AUTOSAR XML (schema 3.1.2)
package /Components/SWC_VSCo
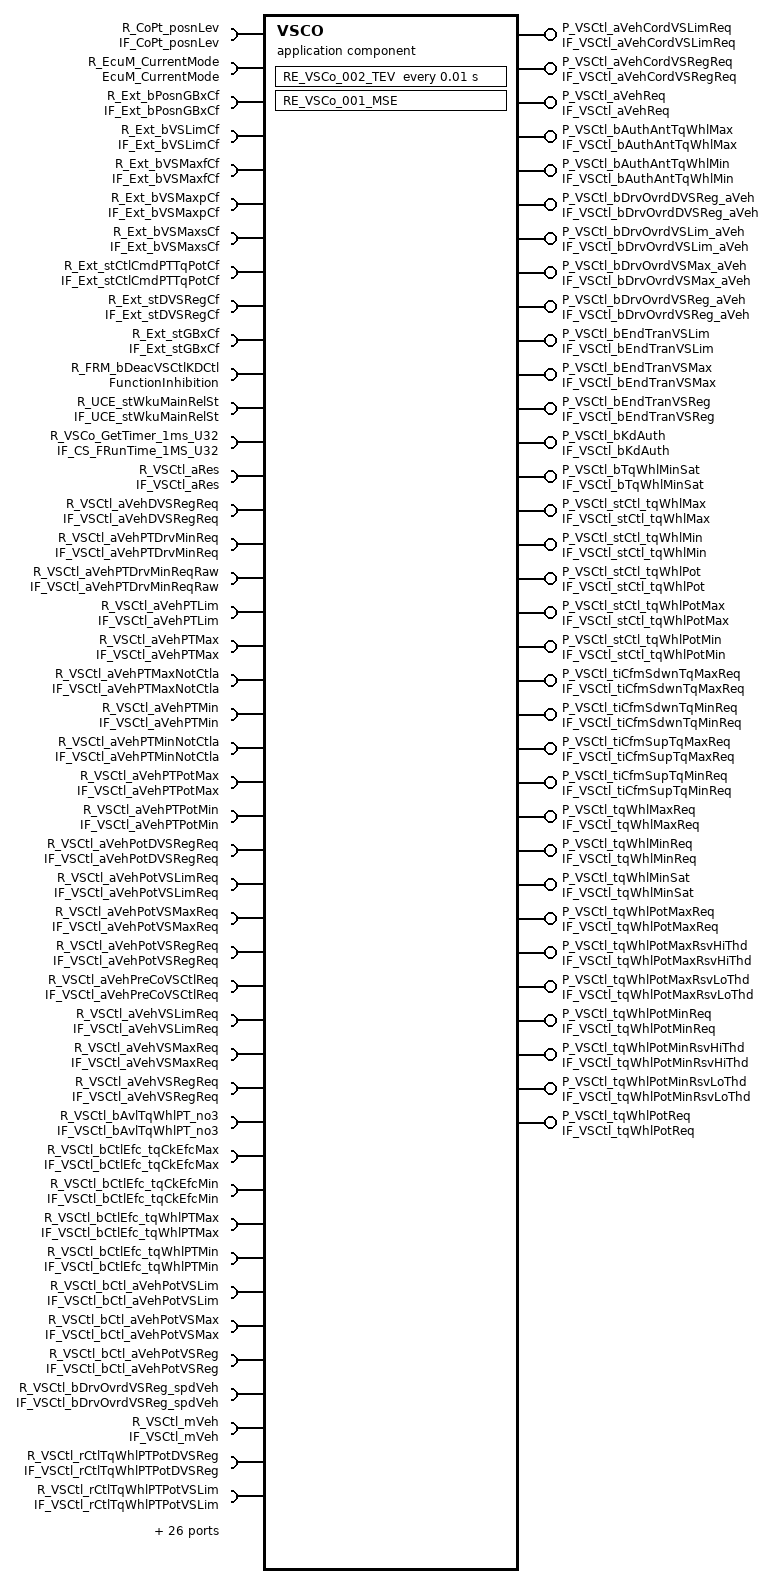
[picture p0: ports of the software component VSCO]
  application software component type VSCO  # VSCo
    33 x provide port:
      P_VSCtl_aVehCordVSLimReq: unqueued-sender-com-spec{data-element=VSCtl_aVehCordVSLimReq, can-invalidate=false, init-value=C_SInt16_10240}, provided-interface=IF_VSCtl_aVehCordVSLimReq
      P_VSCtl_aVehCordVSRegReq: unqueued-sender-com-spec{data-element=VSCtl_aVehCordVSRegReq, can-invalidate=false, init-value=C_SInt16_m10240}, provided-interface=IF_VSCtl_aVehCordVSRegReq
      P_VSCtl_aVehReq: unqueued-sender-com-spec{data-element=VSCtl_aVehReq, can-invalidate=false, init-value=C_SInt16_m102401}, provided-interface=IF_VSCtl_aVehReq
      P_VSCtl_bAuthAntTqWhlMax: unqueued-sender-com-spec{data-element=VSCtl_bAuthAntTqWhlMax, can-invalidate=false, init-value=C_Boolean_False}, provided-interface=IF_VSCtl_bAuthAntTqWhlMax
      P_VSCtl_bAuthAntTqWhlMin: unqueued-sender-com-spec{data-element=VSCtl_bAuthAntTqWhlMin, can-invalidate=false, init-value=C_Boolean_False3}, provided-interface=IF_VSCtl_bAuthAntTqWhlMin
      P_VSCtl_bDrvOvrdDVSReg_aVeh: unqueued-sender-com-spec{data-element=VSCtl_bDrvOvrdDVSReg_aVeh, can-invalidate=false, init-value=C_Boolean_False5}, provided-interface=IF_VSCtl_bDrvOvrdDVSReg_aVeh
      P_VSCtl_bDrvOvrdVSLim_aVeh: unqueued-sender-com-spec{data-element=VSCtl_bDrvOvrdVSLim_aVeh, can-invalidate=false, init-value=C_Boolean_True}, provided-interface=IF_VSCtl_bDrvOvrdVSLim_aVeh
      P_VSCtl_bDrvOvrdVSMax_aVeh: unqueued-sender-com-spec{data-element=VSCtl_bDrvOvrdVSMax_aVeh, can-invalidate=false, init-value=C_Boolean_True7}, provided-interface=IF_VSCtl_bDrvOvrdVSMax_aVeh
      P_VSCtl_bDrvOvrdVSReg_aVeh: unqueued-sender-com-spec{data-element=VSCtl_bDrvOvrdVSReg_aVeh, can-invalidate=false, init-value=C_Boolean_False9}, provided-interface=IF_VSCtl_bDrvOvrdVSReg_aVeh
      P_VSCtl_bEndTranVSLim: unqueued-sender-com-spec{data-element=VSCtl_bEndTranVSLim, can-invalidate=false, init-value=C_Boolean_True11}, provided-interface=IF_VSCtl_bEndTranVSLim
      P_VSCtl_bEndTranVSMax: unqueued-sender-com-spec{data-element=VSCtl_bEndTranVSMax, can-invalidate=false, init-value=C_Boolean_True13}, provided-interface=IF_VSCtl_bEndTranVSMax
      P_VSCtl_bEndTranVSReg: unqueued-sender-com-spec{data-element=VSCtl_bEndTranVSReg, can-invalidate=false, init-value=C_Boolean_True15}, provided-interface=IF_VSCtl_bEndTranVSReg
      P_VSCtl_bKdAuth: unqueued-sender-com-spec{data-element=VSCtl_bKdAuth, can-invalidate=false, init-value=C_Boolean_False17}, provided-interface=IF_VSCtl_bKdAuth
      P_VSCtl_bTqWhlMinSat: unqueued-sender-com-spec{data-element=VSCtl_bTqWhlMinSat, can-invalidate=false, init-value=C_Boolean_False19}, provided-interface=IF_VSCtl_bTqWhlMinSat
      P_VSCtl_stCtl_tqWhlMax: unqueued-sender-com-spec{data-element=VSCtl_stCtl_tqWhlMax, can-invalidate=false, init-value=C_Boolean_False21}, provided-interface=IF_VSCtl_stCtl_tqWhlMax
      P_VSCtl_stCtl_tqWhlMin: unqueued-sender-com-spec{data-element=VSCtl_stCtl_tqWhlMin, can-invalidate=false, init-value=C_Boolean_False23}, provided-interface=IF_VSCtl_stCtl_tqWhlMin
      P_VSCtl_stCtl_tqWhlPot: unqueued-sender-com-spec{data-element=VSCtl_stCtl_tqWhlPot, can-invalidate=false, init-value=C_Boolean_False25}, provided-interface=IF_VSCtl_stCtl_tqWhlPot
      P_VSCtl_stCtl_tqWhlPotMax: unqueued-sender-com-spec{data-element=VSCtl_stCtl_tqWhlPotMax, can-invalidate=false, init-value=C_UInt8_0}, provided-interface=IF_VSCtl_stCtl_tqWhlPotMax
      P_VSCtl_stCtl_tqWhlPotMin: unqueued-sender-com-spec{data-element=VSCtl_stCtl_tqWhlPotMin, can-invalidate=false, init-value=C_UInt8_027}, provided-interface=IF_VSCtl_stCtl_tqWhlPotMin
      P_VSCtl_tiCfmSdwnTqMaxReq: unqueued-sender-com-spec{data-element=VSCtl_tiCfmSdwnTqMaxReq, can-invalidate=false, init-value=C_UInt16_0}, provided-interface=IF_VSCtl_tiCfmSdwnTqMaxReq
      P_VSCtl_tiCfmSdwnTqMinReq: unqueued-sender-com-spec{data-element=VSCtl_tiCfmSdwnTqMinReq, can-invalidate=false, init-value=C_UInt16_029}, provided-interface=IF_VSCtl_tiCfmSdwnTqMinReq
      P_VSCtl_tiCfmSupTqMaxReq: unqueued-sender-com-spec{data-element=VSCtl_tiCfmSupTqMaxReq, can-invalidate=false, init-value=C_UInt16_031}, provided-interface=IF_VSCtl_tiCfmSupTqMaxReq
      P_VSCtl_tiCfmSupTqMinReq: unqueued-sender-com-spec{data-element=VSCtl_tiCfmSupTqMinReq, can-invalidate=false, init-value=C_UInt16_033}, provided-interface=IF_VSCtl_tiCfmSupTqMinReq
      P_VSCtl_tqWhlMaxReq: unqueued-sender-com-spec{data-element=VSCtl_tqWhlMaxReq, can-invalidate=false, init-value=C_SInt16_32000}, provided-interface=IF_VSCtl_tqWhlMaxReq
      P_VSCtl_tqWhlMinReq: unqueued-sender-com-spec{data-element=VSCtl_tqWhlMinReq, can-invalidate=false, init-value=C_SInt16_m32000}, provided-interface=IF_VSCtl_tqWhlMinReq
      P_VSCtl_tqWhlMinSat: unqueued-sender-com-spec{data-element=VSCtl_tqWhlMinSat, can-invalidate=false, init-value=C_SInt16_m3200035}, provided-interface=IF_VSCtl_tqWhlMinSat
      P_VSCtl_tqWhlPotMaxReq: unqueued-sender-com-spec{data-element=VSCtl_tqWhlPotMaxReq, can-invalidate=false, init-value=C_SInt16_3200037}, provided-interface=IF_VSCtl_tqWhlPotMaxReq
      P_VSCtl_tqWhlPotMaxRsvHiThd: unqueued-sender-com-spec{data-element=VSCtl_tqWhlPotMaxRsvHiThd, can-invalidate=false, init-value=C_SInt16_0}, provided-interface=IF_VSCtl_tqWhlPotMaxRsvHiThd
      P_VSCtl_tqWhlPotMaxRsvLoThd: unqueued-sender-com-spec{data-element=VSCtl_tqWhlPotMaxRsvLoThd, can-invalidate=false, init-value=C_SInt16_039}, provided-interface=IF_VSCtl_tqWhlPotMaxRsvLoThd
      P_VSCtl_tqWhlPotMinReq: unqueued-sender-com-spec{data-element=VSCtl_tqWhlPotMinReq, can-invalidate=false, init-value=C_SInt16_m3200041}, provided-interface=IF_VSCtl_tqWhlPotMinReq
      P_VSCtl_tqWhlPotMinRsvHiThd: unqueued-sender-com-spec{data-element=VSCtl_tqWhlPotMinRsvHiThd, can-invalidate=false, init-value=C_SInt16_043}, provided-interface=IF_VSCtl_tqWhlPotMinRsvHiThd
      P_VSCtl_tqWhlPotMinRsvLoThd: unqueued-sender-com-spec{data-element=VSCtl_tqWhlPotMinRsvLoThd, can-invalidate=false, init-value=C_SInt16_045}, provided-interface=IF_VSCtl_tqWhlPotMinRsvLoThd
      P_VSCtl_tqWhlPotReq: unqueued-sender-com-spec{data-element=VSCtl_tqWhlPotReq, can-invalidate=false, init-value=C_SInt16_m3200047}, provided-interface=IF_VSCtl_tqWhlPotReq
    70 x require port:
      R_CoPt_posnLev: unqueued-receiver-com-spec{data-element=CoPt_posnLev, init-value=ConstantValue, resync-time=0}, required-interface=IF_CoPt_posnLev
      R_EcuM_CurrentMode: required-interface=EcuM_CurrentMode  # Requirement: 01552_09_00532-SSTG-C007(2)
      R_Ext_bPosnGBxCf: unqueued-receiver-com-spec{data-element=Ext_bPosnGBxCf, init-value=C_Boolean_False49, resync-time=0}, required-interface=IF_Ext_bPosnGBxCf
      R_Ext_bVSLimCf: unqueued-receiver-com-spec{data-element=Ext_bVSLimCf, init-value=C_Boolean_False51, resync-time=0}, required-interface=IF_Ext_bVSLimCf
      R_Ext_bVSMaxfCf: unqueued-receiver-com-spec{data-element=Ext_bVSMaxfCf, init-value=C_Boolean_False53, resync-time=0}, required-interface=IF_Ext_bVSMaxfCf
      R_Ext_bVSMaxpCf: unqueued-receiver-com-spec{data-element=Ext_bVSMaxpCf, init-value=C_Boolean_False55, resync-time=0}, required-interface=IF_Ext_bVSMaxpCf
      R_Ext_bVSMaxsCf: unqueued-receiver-com-spec{data-element=Ext_bVSMaxsCf, init-value=C_Boolean_False57, resync-time=0}, required-interface=IF_Ext_bVSMaxsCf
      R_Ext_stCtlCmdPTTqPotCf: unqueued-receiver-com-spec{data-element=Ext_stCtlCmdPTTqPotCf, init-value=C_UInt8_059, resync-time=0}, required-interface=IF_Ext_stCtlCmdPTTqPotCf
      R_Ext_stDVSRegCf: unqueued-receiver-com-spec{data-element=Ext_stDVSRegCf, init-value=C_UInt8_061, resync-time=0}, required-interface=IF_Ext_stDVSRegCf
      R_Ext_stGBxCf: unqueued-receiver-com-spec{data-element=Ext_stGBxCf, init-value=ConstantValue63, resync-time=0}, required-interface=IF_Ext_stGBxCf
      R_FRM_bDeacVSCtlKDCtl: required-interface=FunctionInhibition
      R_UCE_stWkuMainRelSt: required-interface=IF_UCE_stWkuMainRelSt  # Requirement: 01552_09_00532-SSTG-C011(1)
      R_VSCo_GetTimer_1ms_U32: required-interface=IF_CS_FRunTime_1MS_U32
      R_VSCtl_aRes: unqueued-receiver-com-spec{data-element=VSCtl_aRes, init-value=C_SInt16_m1024065, resync-time=0}, required-interface=IF_VSCtl_aRes
      R_VSCtl_aVehDVSRegReq: unqueued-receiver-com-spec{data-element=VSCtl_aVehDVSRegReq, init-value=C_SInt16_m1024067, resync-time=0}, required-interface=IF_VSCtl_aVehDVSRegReq
      R_VSCtl_aVehPTDrvMinReq: unqueued-receiver-com-spec{data-element=VSCtl_aVehPTDrvMinReq, init-value=C_SInt16_m1024069, resync-time=0}, required-interface=IF_VSCtl_aVehPTDrvMinReq
      R_VSCtl_aVehPTDrvMinReqRaw: unqueued-receiver-com-spec{data-element=VSCtl_aVehPTDrvMinReqRaw, init-value=C_SInt16_m1024071, resync-time=0}, required-interface=IF_VSCtl_aVehPTDrvMinReqRaw
      R_VSCtl_aVehPTLim: unqueued-receiver-com-spec{data-element=VSCtl_aVehPTLim, init-value=C_SInt16_m1024073, resync-time=0}, required-interface=IF_VSCtl_aVehPTLim
      R_VSCtl_aVehPTMax: unqueued-receiver-com-spec{data-element=VSCtl_aVehPTMax, init-value=C_SInt16_m1024075, resync-time=0}, required-interface=IF_VSCtl_aVehPTMax
      R_VSCtl_aVehPTMaxNotCtla: unqueued-receiver-com-spec{data-element=VSCtl_aVehPTMaxNotCtla, init-value=C_SInt16_m1024077, resync-time=0}, required-interface=IF_VSCtl_aVehPTMaxNotCtla
      R_VSCtl_aVehPTMin: unqueued-receiver-com-spec{data-element=VSCtl_aVehPTMin, init-value=C_SInt16_m1024079, resync-time=0}, required-interface=IF_VSCtl_aVehPTMin
      R_VSCtl_aVehPTMinNotCtla: unqueued-receiver-com-spec{data-element=VSCtl_aVehPTMinNotCtla, init-value=C_SInt16_m1024081, resync-time=0}, required-interface=IF_VSCtl_aVehPTMinNotCtla
      R_VSCtl_aVehPTPotMax: unqueued-receiver-com-spec{data-element=VSCtl_aVehPTPotMax, init-value=C_SInt16_m1024083, resync-time=0}, required-interface=IF_VSCtl_aVehPTPotMax
      R_VSCtl_aVehPTPotMin: unqueued-receiver-com-spec{data-element=VSCtl_aVehPTPotMin, init-value=C_SInt16_m1024085, resync-time=0}, required-interface=IF_VSCtl_aVehPTPotMin
      R_VSCtl_aVehPotDVSRegReq: unqueued-receiver-com-spec{data-element=VSCtl_aVehPotDVSRegReq, init-value=C_SInt16_m1024087, resync-time=0}, required-interface=IF_VSCtl_aVehPotDVSRegReq
      R_VSCtl_aVehPotVSLimReq: unqueued-receiver-com-spec{data-element=VSCtl_aVehPotVSLimReq, init-value=C_SInt16_m1024089, resync-time=0}, required-interface=IF_VSCtl_aVehPotVSLimReq
      R_VSCtl_aVehPotVSMaxReq: unqueued-receiver-com-spec{data-element=VSCtl_aVehPotVSMaxReq, init-value=C_SInt16_m1024091, resync-time=0}, required-interface=IF_VSCtl_aVehPotVSMaxReq
      R_VSCtl_aVehPotVSRegReq: unqueued-receiver-com-spec{data-element=VSCtl_aVehPotVSRegReq, init-value=C_SInt16_m1024093, resync-time=0}, required-interface=IF_VSCtl_aVehPotVSRegReq
      R_VSCtl_aVehPreCoVSCtlReq: unqueued-receiver-com-spec{data-element=VSCtl_aVehPreCoVSCtlReq, init-value=C_SInt16_m1024095, resync-time=0}, required-interface=IF_VSCtl_aVehPreCoVSCtlReq
      R_VSCtl_aVehVSLimReq: unqueued-receiver-com-spec{data-element=VSCtl_aVehVSLimReq, init-value=C_SInt16_m1024097, resync-time=0}, required-interface=IF_VSCtl_aVehVSLimReq
      R_VSCtl_aVehVSMaxReq: unqueued-receiver-com-spec{data-element=VSCtl_aVehVSMaxReq, init-value=C_SInt16_m1024099, resync-time=0}, required-interface=IF_VSCtl_aVehVSMaxReq
      R_VSCtl_aVehVSRegReq: unqueued-receiver-com-spec{data-element=VSCtl_aVehVSRegReq, init-value=C_SInt16_m10240101, resync-time=0}, required-interface=IF_VSCtl_aVehVSRegReq
      R_VSCtl_bAvlTqWhlPT_no3: unqueued-receiver-com-spec{data-element=VSCtl_bAvlTqWhlPT_no3, init-value=C_Boolean_False103, resync-time=0}, required-interface=IF_VSCtl_bAvlTqWhlPT_no3
      R_VSCtl_bCtlEfc_tqCkEfcMax: unqueued-receiver-com-spec{data-element=VSCtl_bCtlEfc_tqCkEfcMax, init-value=C_Boolean_False105, resync-time=0}, required-interface=IF_VSCtl_bCtlEfc_tqCkEfcMax
      R_VSCtl_bCtlEfc_tqCkEfcMin: unqueued-receiver-com-spec{data-element=VSCtl_bCtlEfc_tqCkEfcMin, init-value=C_Boolean_False107, resync-time=0}, required-interface=IF_VSCtl_bCtlEfc_tqCkEfcMin
      R_VSCtl_bCtlEfc_tqWhlPTMax: unqueued-receiver-com-spec{data-element=VSCtl_bCtlEfc_tqWhlPTMax, init-value=C_Boolean_False109, resync-time=0}, required-interface=IF_VSCtl_bCtlEfc_tqWhlPTMax
      R_VSCtl_bCtlEfc_tqWhlPTMin: unqueued-receiver-com-spec{data-element=VSCtl_bCtlEfc_tqWhlPTMin, init-value=C_Boolean_False111, resync-time=0}, required-interface=IF_VSCtl_bCtlEfc_tqWhlPTMin
      R_VSCtl_bCtl_aVehPotVSLim: unqueued-receiver-com-spec{data-element=VSCtl_bCtl_aVehPotVSLim, init-value=C_UInt8_0113, resync-time=0}, required-interface=IF_VSCtl_bCtl_aVehPotVSLim
      R_VSCtl_bCtl_aVehPotVSMax: unqueued-receiver-com-spec{data-element=VSCtl_bCtl_aVehPotVSMax, init-value=C_UInt8_0115, resync-time=0}, required-interface=IF_VSCtl_bCtl_aVehPotVSMax
      R_VSCtl_bCtl_aVehPotVSReg: unqueued-receiver-com-spec{data-element=VSCtl_bCtl_aVehPotVSReg, init-value=C_UInt8_0117, resync-time=0}, required-interface=IF_VSCtl_bCtl_aVehPotVSReg
      R_VSCtl_bDrvOvrdVSReg_spdVeh: unqueued-receiver-com-spec{data-element=VSCtl_bDrvOvrdVSReg_spdVeh, init-value=C_Boolean_False119, resync-time=0}, required-interface=IF_VSCtl_bDrvOvrdVSReg_spdVeh
      R_VSCtl_mVeh: unqueued-receiver-com-spec{data-element=VSCtl_mVeh, init-value=C_UInt16_1, resync-time=0}, required-interface=IF_VSCtl_mVeh
      R_VSCtl_rCtlTqWhlPTPotDVSReg: unqueued-receiver-com-spec{data-element=VSCtl_rCtlTqWhlPTPotDVSReg, init-value=C_UInt16_0121, resync-time=0}, required-interface=IF_VSCtl_rCtlTqWhlPTPotDVSReg
      R_VSCtl_rCtlTqWhlPTPotVSLim: unqueued-receiver-com-spec{data-element=VSCtl_rCtlTqWhlPTPotVSLim, init-value=C_UInt16_0123, resync-time=0}, required-interface=IF_VSCtl_rCtlTqWhlPTPotVSLim
      R_VSCtl_rCtlTqWhlPTPotVSMax: unqueued-receiver-com-spec{data-element=VSCtl_rCtlTqWhlPTPotVSMax, init-value=C_UInt16_0125, resync-time=0}, required-interface=IF_VSCtl_rCtlTqWhlPTPotVSMax
      R_VSCtl_rCtlTqWhlPTPotVSReg: unqueued-receiver-com-spec{data-element=VSCtl_rCtlTqWhlPTPotVSReg, init-value=C_UInt16_0127, resync-time=0}, required-interface=IF_VSCtl_rCtlTqWhlPTPotVSReg
      R_VSCtl_rdWhl: unqueued-receiver-com-spec{data-element=VSCtl_rdWhl, init-value=C_UInt16_1129, resync-time=0}, required-interface=IF_VSCtl_rdWhl
      R_VSCtl_spdVeh: unqueued-receiver-com-spec{data-element=VSCtl_spdVeh, init-value=C_UInt16_0131, resync-time=0}, required-interface=IF_VSCtl_spdVeh
      R_VSCtl_stCtl_aVehDVSReg: unqueued-receiver-com-spec{data-element=VSCtl_stCtl_aVehDVSReg, init-value=C_Boolean_False133, resync-time=0}, required-interface=IF_VSCtl_stCtl_aVehDVSReg
      R_VSCtl_stCtl_aVehPotDVSReg: unqueued-receiver-com-spec{data-element=VSCtl_stCtl_aVehPotDVSReg, init-value=C_UInt8_0135, resync-time=0}, required-interface=IF_VSCtl_stCtl_aVehPotDVSReg
      R_VSCtl_stCtl_aVehVSLim: unqueued-receiver-com-spec{data-element=VSCtl_stCtl_aVehVSLim, init-value=C_UInt8_0137, resync-time=0}, required-interface=IF_VSCtl_stCtl_aVehVSLim
      R_VSCtl_stCtl_aVehVSMax: unqueued-receiver-com-spec{data-element=VSCtl_stCtl_aVehVSMax, init-value=C_UInt8_0139, resync-time=0}, required-interface=IF_VSCtl_stCtl_aVehVSMax
      R_VSCtl_stCtl_aVehVSReg: unqueued-receiver-com-spec{data-element=VSCtl_stCtl_aVehVSReg, init-value=C_UInt8_0141, resync-time=0}, required-interface=IF_VSCtl_stCtl_aVehVSReg
      R_VSCtl_stTqWhlPTCutOffReq: unqueued-receiver-com-spec{data-element=VSCtl_stTqWhlPTCutOffReq, init-value=C_UInt8_0143, resync-time=0}, required-interface=IF_VSCtl_stTqWhlPTCutOffReq
      R_VSCtl_stVSCtlInfo: unqueued-receiver-com-spec{data-element=VSCtl_stVSCtlInfo, init-value=C_UInt8_0145, resync-time=0}, required-interface=IF_VSCtl_stVSCtlInfo
      R_VSCtl_tiCfmSdwnDVSRegReq: unqueued-receiver-com-spec{data-element=VSCtl_tiCfmSdwnDVSRegReq, init-value=C_UInt16_0147, resync-time=0}, required-interface=IF_VSCtl_tiCfmSdwnDVSRegReq
      R_VSCtl_tiCfmSdwnVSLimReq: unqueued-receiver-com-spec{data-element=VSCtl_tiCfmSdwnVSLimReq, init-value=C_UInt16_0149, resync-time=0}, required-interface=IF_VSCtl_tiCfmSdwnVSLimReq
      R_VSCtl_tiCfmSdwnVSMaxReq: unqueued-receiver-com-spec{data-element=VSCtl_tiCfmSdwnVSMaxReq, init-value=C_UInt16_0151, resync-time=0}, required-interface=IF_VSCtl_tiCfmSdwnVSMaxReq
      R_VSCtl_tiCfmSdwnVSRegReq: unqueued-receiver-com-spec{data-element=VSCtl_tiCfmSdwnVSRegReq, init-value=C_UInt16_0153, resync-time=0}, required-interface=IF_VSCtl_tiCfmSdwnVSRegReq
      R_VSCtl_tiCfmSupDVSRegReq: unqueued-receiver-com-spec{data-element=VSCtl_tiCfmSupDVSRegReq, init-value=C_UInt16_0155, resync-time=0}, required-interface=IF_VSCtl_tiCfmSupDVSRegReq
      R_VSCtl_tiCfmSupVSLimReq: unqueued-receiver-com-spec{data-element=VSCtl_tiCfmSupVSLimReq, init-value=C_UInt16_0157, resync-time=0}, required-interface=IF_VSCtl_tiCfmSupVSLimReq
      R_VSCtl_tiCfmSupVSMaxReq: unqueued-receiver-com-spec{data-element=VSCtl_tiCfmSupVSMaxReq, init-value=C_UInt16_0159, resync-time=0}, required-interface=IF_VSCtl_tiCfmSupVSMaxReq
      R_VSCtl_tiCfmSupVSRegReq: unqueued-receiver-com-spec{data-element=VSCtl_tiCfmSupVSRegReq, init-value=C_UInt16_0161, resync-time=0}, required-interface=IF_VSCtl_tiCfmSupVSRegReq
      R_VSCtl_tqWhlPTMax: unqueued-receiver-com-spec{data-element=VSCtl_tqWhlPTMax, init-value=C_SInt16_m32000163, resync-time=0}, required-interface=IF_VSCtl_tqWhlPTMax
      R_VSCtl_tqWhlPTMin: unqueued-receiver-com-spec{data-element=VSCtl_tqWhlPTMin, init-value=C_SInt16_m32000165, resync-time=0}, required-interface=IF_VSCtl_tqWhlPTMin
      R_VSCtl_tqWhlPTPotMax: unqueued-receiver-com-spec{data-element=VSCtl_tqWhlPTPotMax, init-value=C_SInt16_m32000167, resync-time=0}, required-interface=IF_VSCtl_tqWhlPTPotMax
      R_VSCtl_tqWhlPTPotMin: unqueued-receiver-com-spec{data-element=VSCtl_tqWhlPTPotMin, init-value=C_SInt16_m32000169, resync-time=0}, required-interface=IF_VSCtl_tqWhlPTPotMin
      R_VSCtl_tqWhlThPTMin: unqueued-receiver-com-spec{data-element=VSCtl_tqWhlThPTMin, init-value=C_SInt16_m32000171, resync-time=0}, required-interface=IF_VSCtl_tqWhlThPTMin
      R_VSCtl_tqWhlThPTPotMin: unqueued-receiver-com-spec{data-element=VSCtl_tqWhlThPTPotMin, init-value=C_SInt16_m32000173, resync-time=0}, required-interface=IF_VSCtl_tqWhlThPTPotMin
      R_Ext_bCtlCmdPTTqCf: unqueued-receiver-com-spec{data-element=Ext_bCtlCmdPTTqCf, init-value=ConstantValue175, resync-time=0}, required-interface=IF_Ext_bCtlCmdPTTqCf  # R_Ext_bVSMaxpCf
  99 x constant specification:
    C_Boolean_False
      value:
        boolean literal C_Boolean_False: type=DT_VSCtl_bAuthAntTqWhlMax, value=false
    C_Boolean_False103
      value:
        boolean literal C_Boolean_False103: type=DT_VSCtl_bAvlTqWhlPT_no3, value=false
    C_Boolean_False105
      value:
        boolean literal C_Boolean_False105: type=DT_VSCtl_bCtlEfc_tqCkEfcMax, value=false
    C_Boolean_False107
      value:
        boolean literal C_Boolean_False107: type=DT_VSCtl_bCtlEfc_tqCkEfcMin, value=false
    C_Boolean_False109
      value:
        boolean literal C_Boolean_False109: type=DT_VSCtl_bCtlEfc_tqWhlPTMax, value=false
    C_Boolean_False111
      value:
        boolean literal C_Boolean_False111: type=DT_VSCtl_bCtlEfc_tqWhlPTMin, value=false
    C_Boolean_False119
      value:
        boolean literal C_Boolean_False119: type=DT_VSCtl_bDrvOvrdVSReg_spdVeh, value=false
    C_Boolean_False133
      value:
        boolean literal C_Boolean_False133: type=DT_VSCtl_stCtl_aVehDVSReg, value=false
    C_Boolean_False17
      value:
        boolean literal C_Boolean_False17: type=DT_VSCtl_bKdAuth, value=false
    C_Boolean_False19
      value:
        boolean literal C_Boolean_False19: type=DT_VSCtl_bTqWhlMinSat, value=false
    C_Boolean_False21
      value:
        boolean literal C_Boolean_False21: type=DT_VSCtl_stCtl_tqWhlMax, value=false
    C_Boolean_False23
      value:
        boolean literal C_Boolean_False23: type=DT_VSCtl_stCtl_tqWhlMin, value=false
    C_Boolean_False25
      value:
        boolean literal C_Boolean_False25: type=DT_VSCtl_stCtl_tqWhlPot, value=false
    C_Boolean_False3
      value:
        boolean literal C_Boolean_False3: type=DT_VSCtl_bAuthAntTqWhlMin, value=false
    C_Boolean_False49
      value:
        boolean literal C_Boolean_False49: type=DT_Ext_bPosnGBxCf, value=false
    C_Boolean_False5
      value:
        boolean literal C_Boolean_False5: type=DT_VSCtl_bDrvOvrdDVSReg_aVeh, value=false
    C_Boolean_False51
      value:
        boolean literal C_Boolean_False51: type=DT_Ext_bVSLimCf, value=false
    C_Boolean_False53
      value:
        boolean literal C_Boolean_False53: type=DT_Ext_bVSMaxfCf, value=false
    C_Boolean_False55
      value:
        boolean literal C_Boolean_False55: type=DT_Ext_bVSMaxpCf, value=false
    C_Boolean_False57
      value:
        boolean literal C_Boolean_False57: type=DT_Ext_bVSMaxsCf, value=false
    C_Boolean_False9
      value:
        boolean literal C_Boolean_False9: type=DT_VSCtl_bDrvOvrdVSReg_aVeh, value=false
    C_Boolean_True
      value:
        boolean literal C_Boolean_True: type=DT_VSCtl_bDrvOvrdVSLim_aVeh, value=true
    C_Boolean_True11
      value:
        boolean literal C_Boolean_True11: type=DT_VSCtl_bEndTranVSLim, value=true
    C_Boolean_True13
      value:
        boolean literal C_Boolean_True13: type=DT_VSCtl_bEndTranVSMax, value=true
    C_Boolean_True15
      value:
        boolean literal C_Boolean_True15: type=DT_VSCtl_bEndTranVSReg, value=true
    C_Boolean_True7
      value:
        boolean literal C_Boolean_True7: type=DT_VSCtl_bDrvOvrdVSMax_aVeh, value=true
    C_SInt16_0
      value:
        integer literal C_SInt16_0: type=DT_VSCtl_tqWhlPotMaxRsvHiThd, value=0
    C_SInt16_039
      value:
        integer literal C_SInt16_039: type=DT_VSCtl_tqWhlPotMaxRsvLoThd, value=0
    C_SInt16_043
      value:
        integer literal C_SInt16_043: type=DT_VSCtl_tqWhlPotMinRsvHiThd, value=0
    C_SInt16_045
      value:
        integer literal C_SInt16_045: type=DT_VSCtl_tqWhlPotMinRsvLoThd, value=0
    C_SInt16_10240
      value:
        integer literal C_SInt16_10240: type=DT_VSCtl_aVehCordVSLimReq, value=10240
    C_SInt16_32000
      value:
        integer literal C_SInt16_32000: type=DT_VSCtl_tqWhlMaxReq, value=32000
    C_SInt16_3200037
      value:
        integer literal C_SInt16_3200037: type=DT_VSCtl_tqWhlPotMaxReq, value=32000
    C_SInt16_m10240
      value:
        integer literal C_SInt16_m10240: type=DT_VSCtl_aVehCordVSRegReq, value=-10240
    C_SInt16_m102401
      value:
        integer literal C_SInt16_m102401: type=DT_VSCtl_aVehReq, value=-10240
    C_SInt16_m10240101
      value:
        integer literal C_SInt16_m10240101: type=DT_VSCtl_aVehVSRegReq, value=0
    C_SInt16_m1024065
      value:
        integer literal C_SInt16_m1024065: type=DT_VSCtl_aRes, value=0
    C_SInt16_m1024067
      value:
        integer literal C_SInt16_m1024067: type=DT_VSCtl_aVehDVSRegReq, value=-10240
    C_SInt16_m1024069
      value:
        integer literal C_SInt16_m1024069: type=DT_VSCtl_aVehPTDrvMinReq, value=0
    C_SInt16_m1024071
      value:
        integer literal C_SInt16_m1024071: type=DT_VSCtl_aVehPTDrvMinReqRaw, value=0
    C_SInt16_m1024073
      value:
        integer literal C_SInt16_m1024073: type=DT_VSCtl_aVehPTLim, value=0
    C_SInt16_m1024075
      value:
        integer literal C_SInt16_m1024075: type=DT_VSCtl_aVehPTMax, value=0
    C_SInt16_m1024077
      value:
        integer literal C_SInt16_m1024077: type=DT_VSCtl_aVehPTMaxNotCtla, value=0
    C_SInt16_m1024079
      value:
        integer literal C_SInt16_m1024079: type=DT_VSCtl_aVehPTMin, value=0
    C_SInt16_m1024081
      value:
        integer literal C_SInt16_m1024081: type=DT_VSCtl_aVehPTMinNotCtla, value=0
    C_SInt16_m1024083
      value:
        integer literal C_SInt16_m1024083: type=DT_VSCtl_aVehPTPotMax, value=0
    C_SInt16_m1024085
      value:
        integer literal C_SInt16_m1024085: type=DT_VSCtl_aVehPTPotMin, value=0
    C_SInt16_m1024087
      value:
        integer literal C_SInt16_m1024087: type=DT_VSCtl_aVehPotDVSRegReq, value=-10240
    C_SInt16_m1024089
      value:
        integer literal C_SInt16_m1024089: type=DT_VSCtl_aVehPotVSLimReq, value=0
    C_SInt16_m1024091
      value:
        integer literal C_SInt16_m1024091: type=DT_VSCtl_aVehPotVSMaxReq, value=0
    C_SInt16_m1024093
      value:
        integer literal C_SInt16_m1024093: type=DT_VSCtl_aVehPotVSRegReq, value=0
    C_SInt16_m1024095
      value:
        integer literal C_SInt16_m1024095: type=DT_VSCtl_aVehPreCoVSCtlReq, value=0
    C_SInt16_m1024097
      value:
        integer literal C_SInt16_m1024097: type=DT_VSCtl_aVehVSLimReq, value=0
    C_SInt16_m1024099
      value:
        integer literal C_SInt16_m1024099: type=DT_VSCtl_aVehVSMaxReq, value=0
    C_SInt16_m32000
      value:
        integer literal C_SInt16_m32000: type=DT_VSCtl_tqWhlMinReq, value=-32000
    C_SInt16_m32000163
      value:
        integer literal C_SInt16_m32000163: type=DT_VSCtl_tqWhlPTMax, value=0
    C_SInt16_m32000165
      value:
        integer literal C_SInt16_m32000165: type=DT_VSCtl_tqWhlPTMin, value=0
    C_SInt16_m32000167
      value:
        integer literal C_SInt16_m32000167: type=DT_VSCtl_tqWhlPTPotMax, value=0
    C_SInt16_m32000169
      value:
        integer literal C_SInt16_m32000169: type=DT_VSCtl_tqWhlPTPotMin, value=0
    C_SInt16_m32000171
      value:
        integer literal C_SInt16_m32000171: type=DT_VSCtl_tqWhlThPTMin, value=0
    C_SInt16_m32000173
      value:
        integer literal C_SInt16_m32000173: type=DT_VSCtl_tqWhlThPTPotMin, value=0
    C_SInt16_m3200035
      value:
        integer literal C_SInt16_m3200035: type=DT_VSCtl_tqWhlMinSat, value=-32000
    C_SInt16_m3200041
      value:
        integer literal C_SInt16_m3200041: type=DT_VSCtl_tqWhlPotMinReq, value=-32000
    C_SInt16_m3200047
      value:
        integer literal C_SInt16_m3200047: type=DT_VSCtl_tqWhlPotReq, value=-32000
    C_UInt16_0
      value:
        integer literal C_UInt16_0: type=DT_VSCtl_tiCfmSdwnTqMaxReq, value=0
    C_UInt16_0121
      value:
        integer literal C_UInt16_0121: type=DT_VSCtl_rCtlTqWhlPTPotDVSReg, value=0
    C_UInt16_0123
      value:
        integer literal C_UInt16_0123: type=DT_VSCtl_rCtlTqWhlPTPotVSLim, value=0
    C_UInt16_0125
      value:
        integer literal C_UInt16_0125: type=DT_VSCtl_rCtlTqWhlPTPotVSMax, value=0
    C_UInt16_0127
      value:
        integer literal C_UInt16_0127: type=DT_VSCtl_rCtlTqWhlPTPotVSReg, value=0
    C_UInt16_0131
      value:
        integer literal C_UInt16_0131: type=DT_VSCtl_spdVeh, value=0
    C_UInt16_0147
      value:
        integer literal C_UInt16_0147: type=DT_VSCtl_tiCfmSdwnDVSRegReq, value=0
    C_UInt16_0149
      value:
        integer literal C_UInt16_0149: type=DT_VSCtl_tiCfmSdwnVSLimReq, value=0
    C_UInt16_0151
      value:
        integer literal C_UInt16_0151: type=DT_VSCtl_tiCfmSdwnVSMaxReq, value=0
    C_UInt16_0153
      value:
        integer literal C_UInt16_0153: type=DT_VSCtl_tiCfmSdwnVSRegReq, value=0
    C_UInt16_0155
      value:
        integer literal C_UInt16_0155: type=DT_VSCtl_tiCfmSupDVSRegReq, value=0
    C_UInt16_0157
      value:
        integer literal C_UInt16_0157: type=DT_VSCtl_tiCfmSupVSLimReq, value=0
    C_UInt16_0159
      value:
        integer literal C_UInt16_0159: type=DT_VSCtl_tiCfmSupVSMaxReq, value=0
    C_UInt16_0161
      value:
        integer literal C_UInt16_0161: type=DT_VSCtl_tiCfmSupVSRegReq, value=0
    C_UInt16_029
      value:
        integer literal C_UInt16_029: type=DT_VSCtl_tiCfmSdwnTqMinReq, value=0
    C_UInt16_031
      value:
        integer literal C_UInt16_031: type=DT_VSCtl_tiCfmSupTqMaxReq, value=0
    C_UInt16_033
      value:
        integer literal C_UInt16_033: type=DT_VSCtl_tiCfmSupTqMinReq, value=0
    C_UInt16_1
      value:
        integer literal C_UInt16_1: type=DT_VSCtl_mVeh, value=1
    C_UInt16_1129
      value:
        integer literal C_UInt16_1129: type=DT_VSCtl_rdWhl, value=1
    C_UInt8_0
      value:
        integer literal C_UInt8_0: type=DT_VSCtl_stCtl_tqWhlPotMax, value=0
    C_UInt8_0113
      value:
        integer literal C_UInt8_0113: type=DT_VSCtl_bCtl_aVehPotVSLim, value=0
    C_UInt8_0115
      value:
        integer literal C_UInt8_0115: type=DT_VSCtl_bCtl_aVehPotVSMax, value=0
    C_UInt8_0117
      value:
        integer literal C_UInt8_0117: type=DT_VSCtl_bCtl_aVehPotVSReg, value=0
    C_UInt8_0135
      value:
        integer literal C_UInt8_0135: type=DT_VSCtl_stCtl_aVehPotDVSReg, value=0
    C_UInt8_0137
      value:
        integer literal C_UInt8_0137: type=DT_VSCtl_stCtl_aVehVSLim, value=0
    C_UInt8_0139
      value:
        integer literal C_UInt8_0139: type=DT_VSCtl_stCtl_aVehVSMax, value=0
    C_UInt8_0141
      value:
        integer literal C_UInt8_0141: type=DT_VSCtl_stCtl_aVehVSReg, value=0
    C_UInt8_0143
      value:
        integer literal C_UInt8_0143: type=DT_VSCtl_stTqWhlPTCutOffReq, value=0
    C_UInt8_0145
      value:
        integer literal C_UInt8_0145: type=DT_VSCtl_stVSCtlInfo, value=0
    C_UInt8_027
      value:
        integer literal C_UInt8_027: type=DT_VSCtl_stCtl_tqWhlPotMin, value=0
    C_UInt8_059
      value:
        integer literal C_UInt8_059: type=DT_Ext_stCtlCmdPTTqPotCf, value=0
    C_UInt8_061
      value:
        integer literal C_UInt8_061: type=DT_Ext_stDVSRegCf, value=0
    ConstantValue
      value:
        integer literal ConstantValue: type=DT_CoPt_posnLev, value=0
    ConstantValue175
      value:
        boolean literal ConstantValue175: type=DT_Ext_bCtlCmdPTTqCf, value=false
    ConstantValue63
      value:
        integer literal ConstantValue63: type=DT_Ext_stGBxCf, value=0
  internal behavior IB_VSCo: component=VSCO
    mode switch event EV_VSCo_001_MSE: start-on-event=RE_VSCo_001_MSE, activation=ENTRY, mode=R_EcuM_CurrentMode.currentMode.RUN
    timing event EV_VSCo_002_TEV: mode-dependency=dependent-on-mode=[R_UCE_stWkuMainRelSt.RCD_stWkuMainRelSt.Invalid, R_UCE_stWkuMainRelSt.RCD_stWkuMainRelSt.PostMainWakeUp, R_UCE_stWkuMainRelSt.RCD_stWkuMainRelSt.PreMainWakeUp], start-on-event=RE_VSCo_002_TEV, period=0.01
    runnable RE_VSCo_002_TEV  # RE_01552_10_02850_10ms
      66 x data receive point:
        dr_VSCtl_aVehPTMaxNotCtla: data-element=R_VSCtl_aVehPTMaxNotCtla.VSCtl_aVehPTMaxNotCtla
        dr_Ext_bPosnGBxCf: data-element=R_Ext_bPosnGBxCf.Ext_bPosnGBxCf
        dr_VSCtl_aVehPTMin: data-element=R_VSCtl_aVehPTMin.VSCtl_aVehPTMin
        dr_VSCtl_rCtlTqWhlPTPotDVSReg: data-element=R_VSCtl_rCtlTqWhlPTPotDVSReg.VSCtl_rCtlTqWhlPTPotDVSReg
        dr_VSCtl_bDrvOvrdVSReg_spdVeh: data-element=R_VSCtl_bDrvOvrdVSReg_spdVeh.VSCtl_bDrvOvrdVSReg_spdVeh
        dr_VSCtl_stCtl_aVehVSLim: data-element=R_VSCtl_stCtl_aVehVSLim.VSCtl_stCtl_aVehVSLim
        dr_Ext_bVSMaxsCf: data-element=R_Ext_bVSMaxsCf.Ext_bVSMaxsCf
        dr_VSCtl_rCtlTqWhlPTPotVSMax: data-element=R_VSCtl_rCtlTqWhlPTPotVSMax.VSCtl_rCtlTqWhlPTPotVSMax
        dr_VSCtl_spdVeh: data-element=R_VSCtl_spdVeh.VSCtl_spdVeh
        dr_VSCtl_stCtl_aVehVSReg: data-element=R_VSCtl_stCtl_aVehVSReg.VSCtl_stCtl_aVehVSReg
        dr_VSCtl_aVehPreCoVSCtlReq: data-element=R_VSCtl_aVehPreCoVSCtlReq.VSCtl_aVehPreCoVSCtlReq
        dr_VSCtl_bCtlEfc_tqCkEfcMin: data-element=R_VSCtl_bCtlEfc_tqCkEfcMin.VSCtl_bCtlEfc_tqCkEfcMin
        dr_VSCtl_bCtlEfc_tqWhlPTMin: data-element=R_VSCtl_bCtlEfc_tqWhlPTMin.VSCtl_bCtlEfc_tqWhlPTMin
        dr_Ext_stCtlCmdPTTqPotCf: data-element=R_Ext_stCtlCmdPTTqPotCf.Ext_stCtlCmdPTTqPotCf
        dr_VSCtl_aVehPTPotMax: data-element=R_VSCtl_aVehPTPotMax.VSCtl_aVehPTPotMax
        dr_VSCtl_bCtlEfc_tqCkEfcMax: data-element=R_VSCtl_bCtlEfc_tqCkEfcMax.VSCtl_bCtlEfc_tqCkEfcMax
        dr_VSCtl_rdWhl: data-element=R_VSCtl_rdWhl.VSCtl_rdWhl
        dr_VSCtl_aRes: data-element=R_VSCtl_aRes.VSCtl_aRes
        dr_VSCtl_aVehPTPotMin: data-element=R_VSCtl_aVehPTPotMin.VSCtl_aVehPTPotMin
        dr_VSCtl_tiCfmSupDVSRegReq: data-element=R_VSCtl_tiCfmSupDVSRegReq.VSCtl_tiCfmSupDVSRegReq
        dr_VSCtl_tiCfmSupVSMaxReq: data-element=R_VSCtl_tiCfmSupVSMaxReq.VSCtl_tiCfmSupVSMaxReq
        dr_CoPt_posnLev: data-element=R_CoPt_posnLev.CoPt_posnLev
        dr_VSCtl_tiCfmSdwnVSMaxReq: data-element=R_VSCtl_tiCfmSdwnVSMaxReq.VSCtl_tiCfmSdwnVSMaxReq
        dr_VSCtl_tqWhlPTPotMax: data-element=R_VSCtl_tqWhlPTPotMax.VSCtl_tqWhlPTPotMax
        dr_VSCtl_aVehPTMax: data-element=R_VSCtl_aVehPTMax.VSCtl_aVehPTMax
        dr_VSCtl_tqWhlThPTMin: data-element=R_VSCtl_tqWhlThPTMin.VSCtl_tqWhlThPTMin
        dr_VSCtl_bAvlTqWhlPT_no3: data-element=R_VSCtl_bAvlTqWhlPT_no3.VSCtl_bAvlTqWhlPT_no3
        dr_VSCtl_aVehPTMinNotCtla: data-element=R_VSCtl_aVehPTMinNotCtla.VSCtl_aVehPTMinNotCtla
        dr_VSCtl_bCtl_aVehPotVSMax: data-element=R_VSCtl_bCtl_aVehPotVSMax.VSCtl_bCtl_aVehPotVSMax
        dr_VSCtl_bCtlEfc_tqWhlPTMax: data-element=R_VSCtl_bCtlEfc_tqWhlPTMax.VSCtl_bCtlEfc_tqWhlPTMax
        dr_VSCtl_stCtl_aVehVSMax: data-element=R_VSCtl_stCtl_aVehVSMax.VSCtl_stCtl_aVehVSMax
        DRP_R_Ext_bCtlCmdPTTqCf_Ext_bCtlCmdPTTqCf: data-element=R_Ext_bCtlCmdPTTqCf.Ext_bCtlCmdPTTqCf
        dr_VSCtl_aVehPTDrvMinReq: data-element=R_VSCtl_aVehPTDrvMinReq.VSCtl_aVehPTDrvMinReq
        dr_VSCtl_rCtlTqWhlPTPotVSLim: data-element=R_VSCtl_rCtlTqWhlPTPotVSLim.VSCtl_rCtlTqWhlPTPotVSLim
        dr_VSCtl_aVehPotDVSRegReq: data-element=R_VSCtl_aVehPotDVSRegReq.VSCtl_aVehPotDVSRegReq
        dr_Ext_bVSLimCf: data-element=R_Ext_bVSLimCf.Ext_bVSLimCf
        dr_VSCtl_stCtl_aVehDVSReg: data-element=R_VSCtl_stCtl_aVehDVSReg.VSCtl_stCtl_aVehDVSReg
        dr_VSCtl_tqWhlPTMin: data-element=R_VSCtl_tqWhlPTMin.VSCtl_tqWhlPTMin
        dr_Ext_bVSMaxfCf: data-element=R_Ext_bVSMaxfCf.Ext_bVSMaxfCf
        dr_Ext_stGBxCf: data-element=R_Ext_stGBxCf.Ext_stGBxCf
        dr_VSCtl_aVehVSRegReq: data-element=R_VSCtl_aVehVSRegReq.VSCtl_aVehVSRegReq
        dr_Ext_bVSMaxpCf: data-element=R_Ext_bVSMaxpCf.Ext_bVSMaxpCf
        dr_VSCtl_aVehDVSRegReq: data-element=R_VSCtl_aVehDVSRegReq.VSCtl_aVehDVSRegReq
        dr_VSCtl_mVeh: data-element=R_VSCtl_mVeh.VSCtl_mVeh
        dr_VSCtl_tiCfmSdwnVSRegReq: data-element=R_VSCtl_tiCfmSdwnVSRegReq.VSCtl_tiCfmSdwnVSRegReq
        dr_VSCtl_aVehPotVSLimReq: data-element=R_VSCtl_aVehPotVSLimReq.VSCtl_aVehPotVSLimReq
        dr_VSCtl_rCtlTqWhlPTPotVSReg: data-element=R_VSCtl_rCtlTqWhlPTPotVSReg.VSCtl_rCtlTqWhlPTPotVSReg
        dr_VSCtl_tiCfmSdwnDVSRegReq: data-element=R_VSCtl_tiCfmSdwnDVSRegReq.VSCtl_tiCfmSdwnDVSRegReq
        dr_VSCtl_aVehVSLimReq: data-element=R_VSCtl_aVehVSLimReq.VSCtl_aVehVSLimReq
        dr_VSCtl_tiCfmSdwnVSLimReq: data-element=R_VSCtl_tiCfmSdwnVSLimReq.VSCtl_tiCfmSdwnVSLimReq
        dr_VSCtl_tiCfmSupVSLimReq: data-element=R_VSCtl_tiCfmSupVSLimReq.VSCtl_tiCfmSupVSLimReq
        dr_VSCtl_stTqWhlPTCutOffReq: data-element=R_VSCtl_stTqWhlPTCutOffReq.VSCtl_stTqWhlPTCutOffReq
        dr_VSCtl_stVSCtlInfo: data-element=R_VSCtl_stVSCtlInfo.VSCtl_stVSCtlInfo
        dr_VSCtl_bCtl_aVehPotVSLim: data-element=R_VSCtl_bCtl_aVehPotVSLim.VSCtl_bCtl_aVehPotVSLim
        dr_VSCtl_tqWhlThPTPotMin: data-element=R_VSCtl_tqWhlThPTPotMin.VSCtl_tqWhlThPTPotMin
        dr_VSCtl_aVehVSMaxReq: data-element=R_VSCtl_aVehVSMaxReq.VSCtl_aVehVSMaxReq
        dr_VSCtl_stCtl_aVehPotDVSReg: data-element=R_VSCtl_stCtl_aVehPotDVSReg.VSCtl_stCtl_aVehPotDVSReg
        dr_VSCtl_tiCfmSupVSRegReq: data-element=R_VSCtl_tiCfmSupVSRegReq.VSCtl_tiCfmSupVSRegReq
        dr_VSCtl_tqWhlPTPotMin: data-element=R_VSCtl_tqWhlPTPotMin.VSCtl_tqWhlPTPotMin
        dr_VSCtl_aVehPotVSRegReq: data-element=R_VSCtl_aVehPotVSRegReq.VSCtl_aVehPotVSRegReq
        dr_VSCtl_aVehPTLim: data-element=R_VSCtl_aVehPTLim.VSCtl_aVehPTLim
        dr_VSCtl_bCtl_aVehPotVSReg: data-element=R_VSCtl_bCtl_aVehPotVSReg.VSCtl_bCtl_aVehPotVSReg
        dr_Ext_stDVSRegCf: data-element=R_Ext_stDVSRegCf.Ext_stDVSRegCf
        dr_VSCtl_aVehPTDrvMinReqRaw: data-element=R_VSCtl_aVehPTDrvMinReqRaw.VSCtl_aVehPTDrvMinReqRaw
        dr_VSCtl_tqWhlPTMax: data-element=R_VSCtl_tqWhlPTMax.VSCtl_tqWhlPTMax
        dr_VSCtl_aVehPotVSMaxReq: data-element=R_VSCtl_aVehPotVSMaxReq.VSCtl_aVehPotVSMaxReq
      33 x data send point:
        ds_VSCtl_bDrvOvrdVSLim_aVeh: data-element=P_VSCtl_bDrvOvrdVSLim_aVeh.VSCtl_bDrvOvrdVSLim_aVeh
        ds_VSCtl_tqWhlPotMaxRsvHiThd: data-element=P_VSCtl_tqWhlPotMaxRsvHiThd.VSCtl_tqWhlPotMaxRsvHiThd
        ds_VSCtl_tqWhlMaxReq: data-element=P_VSCtl_tqWhlMaxReq.VSCtl_tqWhlMaxReq
        ds_VSCtl_tqWhlPotMinRsvHiThd: data-element=P_VSCtl_tqWhlPotMinRsvHiThd.VSCtl_tqWhlPotMinRsvHiThd
        ds_VSCtl_tiCfmSupTqMaxReq: data-element=P_VSCtl_tiCfmSupTqMaxReq.VSCtl_tiCfmSupTqMaxReq
        ds_VSCtl_bDrvOvrdDVSReg_aVeh: data-element=P_VSCtl_bDrvOvrdDVSReg_aVeh.VSCtl_bDrvOvrdDVSReg_aVeh
        ds_VSCtl_bKdAuth: data-element=P_VSCtl_bKdAuth.VSCtl_bKdAuth
        ds_VSCtl_bTqWhlMinSat: data-element=P_VSCtl_bTqWhlMinSat.VSCtl_bTqWhlMinSat
        ds_VSCtl_bAuthAntTqWhlMax: data-element=P_VSCtl_bAuthAntTqWhlMax.VSCtl_bAuthAntTqWhlMax
        ds_VSCtl_aVehCordVSRegReq: data-element=P_VSCtl_aVehCordVSRegReq.VSCtl_aVehCordVSRegReq
        ds_VSCtl_tqWhlPotMinRsvLoThd: data-element=P_VSCtl_tqWhlPotMinRsvLoThd.VSCtl_tqWhlPotMinRsvLoThd
        ds_VSCtl_bEndTranVSMax: data-element=P_VSCtl_bEndTranVSMax.VSCtl_bEndTranVSMax
        ds_VSCtl_tqWhlPotMaxReq: data-element=P_VSCtl_tqWhlPotMaxReq.VSCtl_tqWhlPotMaxReq
        ds_VSCtl_bEndTranVSLim: data-element=P_VSCtl_bEndTranVSLim.VSCtl_bEndTranVSLim
        ds_VSCtl_tqWhlPotMaxRsvLoThd: data-element=P_VSCtl_tqWhlPotMaxRsvLoThd.VSCtl_tqWhlPotMaxRsvLoThd
        ds_VSCtl_tqWhlPotReq: data-element=P_VSCtl_tqWhlPotReq.VSCtl_tqWhlPotReq
        ds_VSCtl_tiCfmSdwnTqMinReq: data-element=P_VSCtl_tiCfmSdwnTqMinReq.VSCtl_tiCfmSdwnTqMinReq
        ds_VSCtl_bAuthAntTqWhlMin: data-element=P_VSCtl_bAuthAntTqWhlMin.VSCtl_bAuthAntTqWhlMin
        ds_VSCtl_tqWhlMinSat: data-element=P_VSCtl_tqWhlMinSat.VSCtl_tqWhlMinSat
        ds_VSCtl_stCtl_tqWhlPotMax: data-element=P_VSCtl_stCtl_tqWhlPotMax.VSCtl_stCtl_tqWhlPotMax
        ds_VSCtl_stCtl_tqWhlMax: data-element=P_VSCtl_stCtl_tqWhlMax.VSCtl_stCtl_tqWhlMax
        ds_VSCtl_aVehCordVSLimReq: data-element=P_VSCtl_aVehCordVSLimReq.VSCtl_aVehCordVSLimReq
        ds_VSCtl_stCtl_tqWhlPot: data-element=P_VSCtl_stCtl_tqWhlPot.VSCtl_stCtl_tqWhlPot
        ds_VSCtl_stCtl_tqWhlPotMin: data-element=P_VSCtl_stCtl_tqWhlPotMin.VSCtl_stCtl_tqWhlPotMin
        ds_VSCtl_tiCfmSupTqMinReq: data-element=P_VSCtl_tiCfmSupTqMinReq.VSCtl_tiCfmSupTqMinReq
        ds_VSCtl_stCtl_tqWhlMin: data-element=P_VSCtl_stCtl_tqWhlMin.VSCtl_stCtl_tqWhlMin
        ds_VSCtl_aVehReq: data-element=P_VSCtl_aVehReq.VSCtl_aVehReq
        ds_VSCtl_bDrvOvrdVSMax_aVeh: data-element=P_VSCtl_bDrvOvrdVSMax_aVeh.VSCtl_bDrvOvrdVSMax_aVeh
        ds_VSCtl_tiCfmSdwnTqMaxReq: data-element=P_VSCtl_tiCfmSdwnTqMaxReq.VSCtl_tiCfmSdwnTqMaxReq
        ds_VSCtl_bEndTranVSReg: data-element=P_VSCtl_bEndTranVSReg.VSCtl_bEndTranVSReg
        ds_VSCtl_tqWhlMinReq: data-element=P_VSCtl_tqWhlMinReq.VSCtl_tqWhlMinReq
        ds_VSCtl_tqWhlPotMinReq: data-element=P_VSCtl_tqWhlPotMinReq.VSCtl_tqWhlPotMinReq
        ds_VSCtl_bDrvOvrdVSReg_aVeh: data-element=P_VSCtl_bDrvOvrdVSReg_aVeh.VSCtl_bDrvOvrdVSReg_aVeh
      sync call ssp_GetTimer_1ms_U32: operation=R_VSCo_GetTimer_1ms_U32.GetTimer_1ms_U32
      sync call ssp_FRM_bDeacVSCtlKDCtl: operation=R_FRM_bDeacVSCtlKDCtl.GetFunctionPermission
    runnable RE_VSCo_001_MSE  # RE_01552_10_02850_10ms_init
      33 x data send point:
        ds_VSCtl_bAuthAntTqWhlMin: data-element=P_VSCtl_bAuthAntTqWhlMin.VSCtl_bAuthAntTqWhlMin
        ds_VSCtl_bKdAuth: data-element=P_VSCtl_bKdAuth.VSCtl_bKdAuth
        ds_VSCtl_tqWhlPotMinReq: data-element=P_VSCtl_tqWhlPotMinReq.VSCtl_tqWhlPotMinReq
        ds_VSCtl_bEndTranVSReg: data-element=P_VSCtl_bEndTranVSReg.VSCtl_bEndTranVSReg
        ds_VSCtl_stCtl_tqWhlMax: data-element=P_VSCtl_stCtl_tqWhlMax.VSCtl_stCtl_tqWhlMax
        ds_VSCtl_tqWhlPotMinRsvLoThd: data-element=P_VSCtl_tqWhlPotMinRsvLoThd.VSCtl_tqWhlPotMinRsvLoThd
        ds_VSCtl_stCtl_tqWhlPot: data-element=P_VSCtl_stCtl_tqWhlPot.VSCtl_stCtl_tqWhlPot
        ds_VSCtl_tiCfmSupTqMinReq: data-element=P_VSCtl_tiCfmSupTqMinReq.VSCtl_tiCfmSupTqMinReq
        ds_VSCtl_tqWhlMinSat: data-element=P_VSCtl_tqWhlMinSat.VSCtl_tqWhlMinSat
        ds_VSCtl_bEndTranVSLim: data-element=P_VSCtl_bEndTranVSLim.VSCtl_bEndTranVSLim
        ds_VSCtl_tqWhlMaxReq: data-element=P_VSCtl_tqWhlMaxReq.VSCtl_tqWhlMaxReq
        ds_VSCtl_bEndTranVSMax: data-element=P_VSCtl_bEndTranVSMax.VSCtl_bEndTranVSMax
        ds_VSCtl_aVehCordVSRegReq: data-element=P_VSCtl_aVehCordVSRegReq.VSCtl_aVehCordVSRegReq
        ds_VSCtl_stCtl_tqWhlMin: data-element=P_VSCtl_stCtl_tqWhlMin.VSCtl_stCtl_tqWhlMin
        ds_VSCtl_tiCfmSupTqMaxReq: data-element=P_VSCtl_tiCfmSupTqMaxReq.VSCtl_tiCfmSupTqMaxReq
        ds_VSCtl_aVehReq: data-element=P_VSCtl_aVehReq.VSCtl_aVehReq
        ds_VSCtl_tiCfmSdwnTqMinReq: data-element=P_VSCtl_tiCfmSdwnTqMinReq.VSCtl_tiCfmSdwnTqMinReq
        ds_VSCtl_aVehCordVSLimReq: data-element=P_VSCtl_aVehCordVSLimReq.VSCtl_aVehCordVSLimReq
        ds_VSCtl_tqWhlMinReq: data-element=P_VSCtl_tqWhlMinReq.VSCtl_tqWhlMinReq
        ds_VSCtl_tqWhlPotMaxRsvLoThd: data-element=P_VSCtl_tqWhlPotMaxRsvLoThd.VSCtl_tqWhlPotMaxRsvLoThd
        ds_VSCtl_bDrvOvrdVSLim_aVeh: data-element=P_VSCtl_bDrvOvrdVSLim_aVeh.VSCtl_bDrvOvrdVSLim_aVeh
        ds_VSCtl_tqWhlPotMaxRsvHiThd: data-element=P_VSCtl_tqWhlPotMaxRsvHiThd.VSCtl_tqWhlPotMaxRsvHiThd
        ds_VSCtl_bDrvOvrdDVSReg_aVeh: data-element=P_VSCtl_bDrvOvrdDVSReg_aVeh.VSCtl_bDrvOvrdDVSReg_aVeh
        ds_VSCtl_tqWhlPotMinRsvHiThd: data-element=P_VSCtl_tqWhlPotMinRsvHiThd.VSCtl_tqWhlPotMinRsvHiThd
        ds_VSCtl_tiCfmSdwnTqMaxReq: data-element=P_VSCtl_tiCfmSdwnTqMaxReq.VSCtl_tiCfmSdwnTqMaxReq
        ds_VSCtl_stCtl_tqWhlPotMax: data-element=P_VSCtl_stCtl_tqWhlPotMax.VSCtl_stCtl_tqWhlPotMax
        ds_VSCtl_bAuthAntTqWhlMax: data-element=P_VSCtl_bAuthAntTqWhlMax.VSCtl_bAuthAntTqWhlMax
        ds_VSCtl_bTqWhlMinSat: data-element=P_VSCtl_bTqWhlMinSat.VSCtl_bTqWhlMinSat
        ds_VSCtl_tqWhlPotReq: data-element=P_VSCtl_tqWhlPotReq.VSCtl_tqWhlPotReq
        ds_VSCtl_stCtl_tqWhlPotMin: data-element=P_VSCtl_stCtl_tqWhlPotMin.VSCtl_stCtl_tqWhlPotMin
        ds_VSCtl_bDrvOvrdVSReg_aVeh: data-element=P_VSCtl_bDrvOvrdVSReg_aVeh.VSCtl_bDrvOvrdVSReg_aVeh
        ds_VSCtl_tqWhlPotMaxReq: data-element=P_VSCtl_tqWhlPotMaxReq.VSCtl_tqWhlPotMaxReq
        ds_VSCtl_bDrvOvrdVSMax_aVeh: data-element=P_VSCtl_bDrvOvrdVSMax_aVeh.VSCtl_bDrvOvrdVSMax_aVeh
      sync call ssp_GetTimer_1ms_U32: operation=R_VSCo_GetTimer_1ms_U32.GetTimer_1ms_U32
  swc implementation Imp_VSCo: programming-language=C, behavior=IB_VSCo
    code-descriptors:
      code CodeDescriptor: type=SRC
        7 x xfile:
          VSCo_MemMap_h: url=VSCo_MemMap.h
          VSCo_h: url=VSCo.h
          VSCo_c: url=VSCo.c
          VSCO_Whl_Tq_Pot_Cons_Kick_c: url=VSCO_Whl_Tq_Pot_Cons_Kick.c
          VSCO_Veh_Acc_Pot_Act_Cons_c: url=VSCO_Veh_Acc_Pot_Act_Cons.c
          VSCO_Veh_Accel_Cons_c: url=VSCO_Veh_Accel_Cons.c
          VSCO_Wheel_Torque_Cons_c: url=VSCO_Wheel_Torque_Cons.c
